VERSION ""

NS_ :

BS_:

BU_: PC STM32

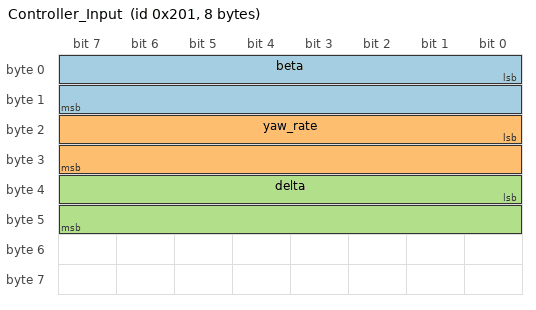
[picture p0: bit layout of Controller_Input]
BO_ 513 Controller_Input: 8 PC
 SG_ beta : 0|16@1- (0.0001,0) [-3.2768|3.2767] "rad" STM32
 SG_ yaw_rate : 16|16@1- (0.0001,0) [-3.2768|3.2767] "rad/s" STM32
 SG_ delta : 32|16@1- (0.0001,0) [-3.2768|3.2767] "rad" STM32

BO_ 515 Controller_Output: 4 STM32
 SG_ M : 0|32@1+ (1,0) [-3.4028235e38|3.4028235e38] "Nm" PC

SIG_VALTYPE_ 515 M : 1;
